# ioSTC8A8K32S2A12 register map
Registers from a debugger description file.
Registers are 8-bit, access not given, no defined reset value unless marked. A register's access mark holds for its fields unless they carry their own. Addresses are absolute; registers are grouped by the start of their names; lines under a group give offsets from that group; [hi:lo] are bit positions; {n}, {i} and the like mark numbered series; 'fields as' and 'values as' point back to an identical list; <NAME> marks a mode.

## Further device data
interrupts=NMI 0x00 1; INT0 0x03 2 IE.EX0 TCON.IE0; Timer0 0x0B 2 IE.ET0 TCON.TF0; INT1 0x13 2 IE.EX1 TCON.IE1; Timer1 0x1B 2 IE.ET1 TCON.TF1; ADC 0x2B 2 IE.EADC ADC_CONTR.ADC_FLAG; LVD 0x33 2 IE.ELVD PCON.LVDF; PCA 0x3B 2 CMOD.ECF CMPCR1.CMPIF; UART2 0x43 2 IE2.ES2 S2CON.S2RI; SPI 0x4B 2 IE2.ESPI SPSTAT.SPIF; INT2 0x53 2 INTCLKO.EX2 AUXINTIF.INT2IF; INT3 0x5B 2 INTCLKO.EX3 AUXINTIF.INT3IF; Timer2 0x63 2 IE2.ET2 AUXINTIF.T2IF; INT4 0x83 2 INTCLKO.EX4 AUXINTIF.INT4IF; UART3 0x8B 2 IE2.ES3 S3CON.S3RI; UART4 0x93 2 IE2.ES4 S4CON.S4RI; Timer3 0x9B 2 IE2.ET3 AUXINTIF.T3IF; Timer4 0xA3 2 IE2.ET4 AUXINTIF.T4IF; CMP 0xAB 2 CMPCR1.PIE CMPCR1.CMPIF; PWM 0xB3 2 PWMCR.ECBI PWMCFG.CBIF; PWMFD 0xBB 2 PWMFDCR.EFDI PWMFDCR.FDIF; I2C 0xC3 2 I2CMSCR.EMSI I2CMSST.MSIF

## SFR_XData
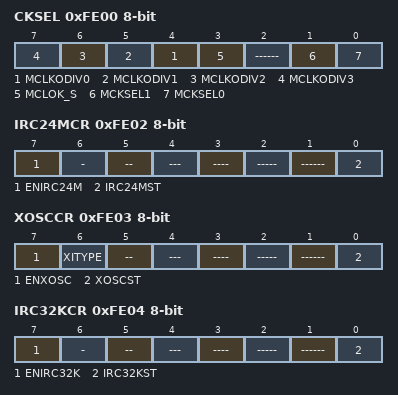
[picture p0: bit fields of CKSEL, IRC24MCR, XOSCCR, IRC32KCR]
0xFE00 CKSEL — Clock select register
  [n+4] MCLKODIV{n} (n=0..3), [3] MCLOK_S, [2] ------, [1] MCKSEL1, [0] MCKSEL0
0xFE01 CLKDIV — Clock division register
0xFE02 IRC24MCR — 24M RC control register
  [7] ENIRC24M, [6] -, [5] --, [4] ---, [3] ----, [2] -----, [1] ------, [0] IRC24MST
0xFE03 XOSCCR — External crystal oscillator control register
  [7] ENXOSC, [6] XITYPE, [5] --, [4] ---, [3] ----, [2] -----, [1] ------, [0] XOSCST
0xFE04 IRC32KCR — 24M RC control register
  [7] ENIRC32K, [6] -, [5] --, [4] ---, [3] ----, [2] -----, [1] ------, [0] IRC32KST
{0xFE10+i} P{i}PU (i=0..5) — Port {i} Pull up control register
0xFE16 P6PU — Port 7 Pull up control register
0xFE17 P7PU — Port 7 Pull up control register
{0xFE18+i} P{i}NCS (i=0..5) — Port {i} Schmidt trigger control register
0xFE1E P6NCS — Port 7 Schmidt trigger control register
0xFE1F P7NCS — Port 7 Schmidt trigger control register
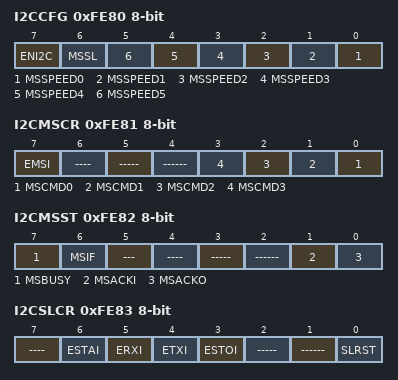
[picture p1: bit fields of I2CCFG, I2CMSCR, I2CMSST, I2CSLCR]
0xFE80 I2CCFG — I2C Config register
  [7] ENI2C, [6] MSSL, [n] MSSPEED{n} (n=0..5)
0xFE81 I2CMSCR — I2C Master control register
  [7] EMSI, [6] ----, [5] -----, [4] ------, [n] MSCMD{n} (n=0..3)
0xFE82 I2CMSST — I2C Master state register
  [7] MSBUSY, [6] MSIF, [5] ---, [4] ----, [3] -----, [2] ------, [1] MSACKI, [0] MSACKO
0xFE83 I2CSLCR — I2C slave control register
  [7] ----, [6] ESTAI, [5] ERXI, [4] ETXI, [3] ESTOI, [2] -----, [1] ------, [0] SLRST
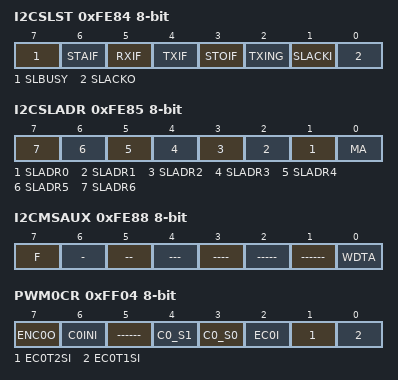
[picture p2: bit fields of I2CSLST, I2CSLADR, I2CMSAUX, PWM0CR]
0xFE84 I2CSLST — I2C slave state register
  [7] SLBUSY, [6] STAIF, [5] RXIF, [4] TXIF, [3] STOIF, [2] TXING, [1] SLACKI, [0] SLACKO
0xFE85 I2CSLADR — I2C slave address register
  [n+1] SLADR{n} (n=0..6), [0] MA
0xFE86 I2CTXD — I2C Tx data register
0xFE87 I2CRXD — I2C Rx data register
0xFE88 I2CMSAUX — I2C Master aux control register
  [7] F, [6] -, [5] --, [4] ---, [3] ----, [2] -----, [1] ------, [0] WDTA
0xFF00 PWM0T1H — PWM0T1 Count High
0xFF01 PWM0T1L — PWM0T1 Count Low
{0xFF02+0x10*i} PWM{i}T2H (i=0..7) — PWM{i}T2 Count High
{0xFF03+0x10*i} PWM{i}T2L (i=0..7) — PWM{i}T2 Count Low
0xFF04 PWM0CR — PWM0 control register
  [7] ENC0O, [6] C0INI, [5] ------, [4] C0_S1, [3] C0_S0, [2] EC0I, [1] EC0T2SI, [0] EC0T1SI
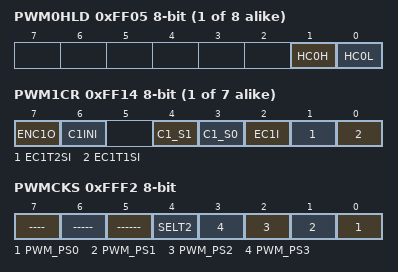
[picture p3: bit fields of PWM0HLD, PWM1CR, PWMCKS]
{0xFF05+0x10*i} PWM{i}HLD (i=0..7) — PWM{i} electrical level hold
  [1] HC{i}H, [0] HC{i}L
0xFF10 PWM1T1H — PWM1T1 Count High
0xFF11 PWM1T1L — PWM1T1 Count Low
{0xFF04+0x10*i} PWM{i}CR (i=1..7) — PWM{i} control register
  [7] ENC{i}O, [6] C{i}INI, [4] C{i}_S1, [3] C{i}_S0, [2] EC{i}I, [1] EC{i}T2SI, [0] EC{i}T1SI
{0xFF00+0x10*i} PWM{i}T1H (i=2..7) — PWM{i}T1H Count High
{0xFF01+0x10*i} PWM{i}T1L (i=2..7) — PWM{i}T1L Count Low
0xFFF0 PWMCH — PWM Counter High
0xFFF1 PWMCL — PWM Counter Low
0xFFF2 PWMCKS — PWM Clock Select
  [7] ----, [6] -----, [5] ------, [4] SELT2, [n] PWM_PS{n} (n=0..3)
0xFFF3 TADCPH — Trigger ADC Count High
0xFFF4 TADCPL — Trigger ADC Count Low
